# NANO112AN_v1 register map
File version: 1.0
NANO112AN_v1 SVD file
Registers are 32-bit, read-write, reset 0x0 unless marked. A register's access mark holds for its fields unless they carry their own. Offsets are from the block's base; lines under a group give offsets from that group; [hi:lo] are bit positions; {n}, {i} and the like mark numbered series; 'fields as' and 'values as' point back to an identical list; <NAME> marks a mode.

## Memory map
0x40004000 WDT size 0xC — WDT Register Map
0x40004100 WWDT size 0x14 — WWDT Register Map
0x40008000 RTC blocks up to offset 0x90 — RTC Register Map
0x40010000 TMR0 blocks up to offset 0x218 — TMR Register Map
0x40010100 TMR1 blocks up to offset 0x24 — TMR Register Map
0x40020000 I2C0 blocks up to offset 0x44 — I2C Register Map
0x40030000 SPI0 blocks up to offset 0x54 — SPI Register Map
0x40040000 PWM blocks up to offset 0x90 — PWM Register Map
0x40050000 UART0 blocks up to offset 0x40 — UART Register Map
0x400B0000 LCD blocks up to offset 0x38 — LCD Register Map
0x400E0000 ADC blocks up to offset 0x78 — ADC Register Map
0x40110000 TMR2 blocks up to offset 0x24 — TMR Register Map
0x40110100 TMR3 blocks up to offset 0x24 — TMR Register Map
0x40120000 I2C1 blocks up to offset 0x44 — I2C Register Map
0x40130000 SPI1 blocks up to offset 0x54 — SPI Register Map
0x40150000 UART1 blocks up to offset 0x40 — UART Register Map
0x40190000 SC0 size 0x40 — SC Register Map
0x401B0000 SC1 size 0x40 — SC Register Map
0x401D0000 ACMP size 0x14 — ACMP Register Map
0x50000000 GCR blocks up to offset 0x104 — GCR Register Map
0x50000200 CLK blocks up to offset 0x44 — CLK Register Map
0x50000300 INT size 0x88 — SCS Register Map
0x50004000 GP blocks up to offset 0x358 — GP Register Map
0x50008100 PDMA_CH1 blocks up to offset 0x2C — PDMA Register Map
0x50008200 PDMA_CH2 blocks up to offset 0x2C — PDMA Register Map
0x50008300 PDMA_CH3 blocks up to offset 0x2C — PDMA Register Map
0x50008400 PDMA_CH4 blocks up to offset 0x2C — PDMA Register Map
0x50008E00 CRC blocks up to offset 0x8C — PDMA Register Map
0x50008F00 DMA_GCR size 0x10 — PDMA Register Map
0x5000C000 FMC blocks up to offset 0x44 — FMC Register Map
0xE000E000 SCS blocks up to offset 0xD24 — SCS Register Map

## FMC — FMC Register Map
Base 0x5000C000
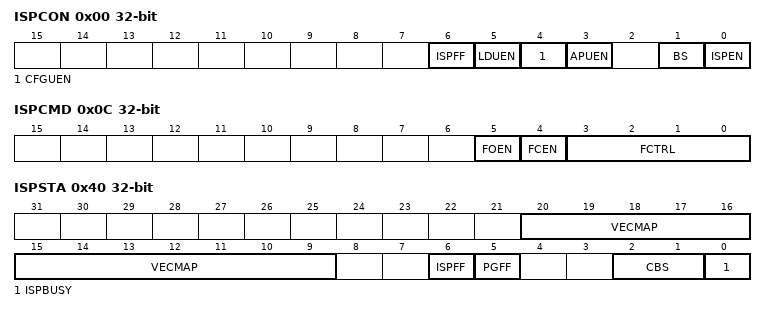
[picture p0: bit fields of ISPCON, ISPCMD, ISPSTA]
0x00 ISPCON — ISP Control Register
  [6] ISPFF — ISP Fail Flag (Write Protect). This bit is set by hardware when a triggered ISP meets any of the following conditions: (3) User Configuration is erased/programmed when CFGUEN is 0. (4) Destination address is illegal, such as over an available range. Note: Write 1 to clear this bit to 0.
  [5] LDUEN — LDROM Update Enable Control (Write Protect)
    0=LDROM cannot be updated; 1=LDROM can be updated
  [4] CFGUEN — Enable Config-bits Update by ISP (Write Protect)
    0=ISP update User Configuration Disabled; 1=ISP update User Configuration Enabled
  [3] APUEN — APROM Update Enable Control (Write Protect)
    0=APROM cannot be updated; 1=APROM can be updated
  [1] BS — Boot Select (Write Protect). Set/clear this bit to select next booting from LDROM/APROM, respectively. This bit also functions as chip booting status flag, which can be used to check where chip booted from. This bit is initiated with the inversed value of CBS in Config0 after power-on reset; It keeps the same value at other reset.
    0=Boot from APROM; 1=Boot from LDROM
  [0] ISPEN — ISP Enable Control (Write Protect). ISP function enable bit. Set this bit to enable ISP function.
    0=ISP function Disabled; 1=ISP function Enabled
0x04 ISPADR — ISP Address Register
  [31:0] ISPADR — ISP Address. This chip supports word program only. ISPADR[1:0] must be kept 00b for ISP operation, and ISPADR[8:0] must be kept all 0 for Vector Page Re-map Command
0x08 ISPDAT — ISP Data Register
  [31:0] ISPDAT — ISP Data. Write data to this register before ISP program operation. Read data from this register after ISP read operation
0x0C ISPCMD — ISP Command Register
  [5] FOEN — ISP Command. The ISP command table is shown as follows.
  [4] FCEN — ISP Command. The ISP command table is shown as follows.
  [3:0] FCTRL — ISP Command. The ISP command table is shown as follows.
0x10 ISPTRG — ISP Trigger Register
  [0] ISPGO — ISP Start Trigger. Write 1 to start ISP operation and this bit will be cleared to 0 by hardware automatically when ISP operation is finished.
    0=ISP operation is finished; 1=ISP is progressing
0x14 DFBADR ro reset 0x1F000 — Data Flash Base Address Register
  [31:0] DFBADR — Data Flash Base Address. This register indicates data flash start address. It is a read only register. The data flash start address is defined by user. Since on chip flash erase unit is 512 bytes, it is mandatory to keep bit 8-0 as 0.
0x40 ISPSTA — ISP Status Register
  [20:9] VECMAP ro — Vector Page Mapping Address (Read Only). The current system memory space 0x0000_0000~0x0000_01FF is mapped to flash memory page with base address (VECMAP[11:0] 9).
  [6] ISPFF — ISP Fail Flag (3) User Configuration is erased/programmed when CFGUEN is 0. (4) Destination address is illegal, such as over an available range. Note: Write 1 to clear this bit to 0.
  [5] PGFF — Auto Flash Program Verified Fail Flag. This chip will perform flash verification automatically at the end of ISP PROGRAM operation, and set 1 to this bit when flash data is not matched with programming. This bit is clear to 0 by "ERASE" command.
  [2:1] CBS ro — Config Boot Selection Status (Read Only). This filed is a mirror of CBS in CONFIG0.
  [0] ISPBUSY ro — ISP Busy (Read Only)
    0=ISP operation is finished; 1=ISP operation is busy
